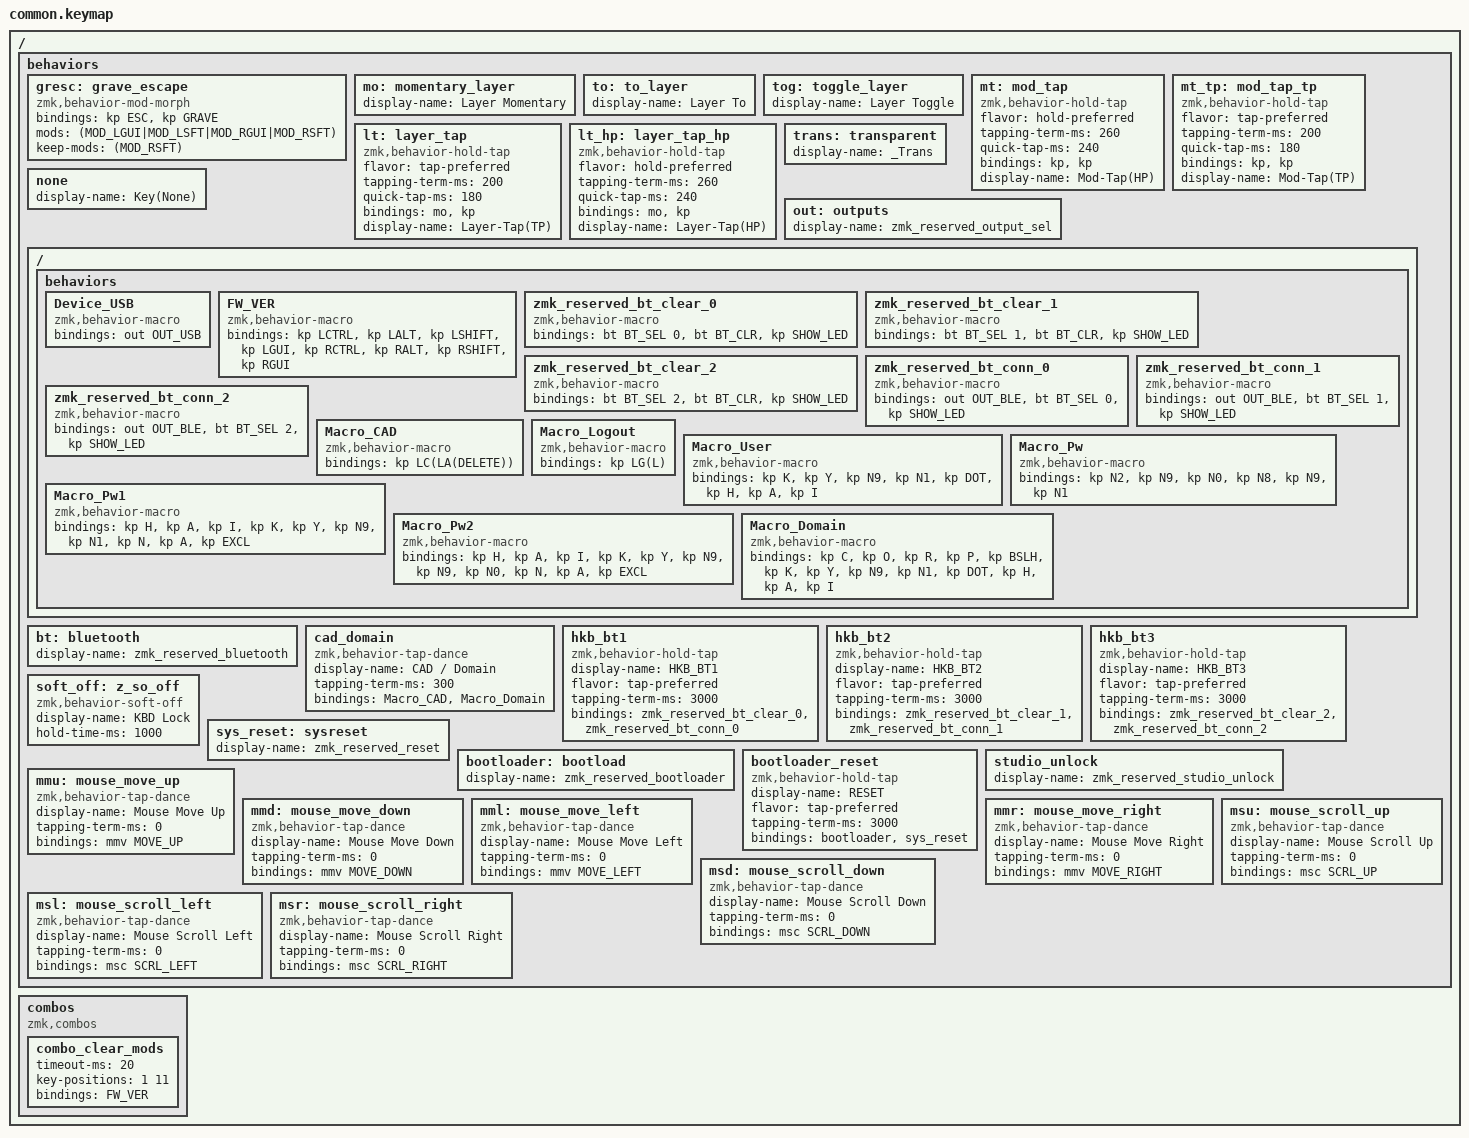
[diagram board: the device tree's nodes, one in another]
/*
 * Copyright (c) 2021 The ZMK Contributors
 *
 * SPDX-License-Identifier: MIT
 */
#define FW_VER zmk_firmware_version_260511
 
#if 1
#define ZMK_BEHAVIORS_OMIT_CAPS_WORD        // &caps_word
#define ZMK_BEHAVIORS_OMIT_KT               // &kt, Key Toggle
#define ZMK_BEHAVIORS_OMIT_KEY_REPEAT       // &key_repeat, Key Repeat
#define ZMK_BEHAVIORS_OMIT_SK               // &sk, Sticky Key
#define ZMK_BEHAVIORS_OMIT_STICKY_LAYER     // &sl, Sticky Layer
#endif

#include <behaviors.dtsi>
#include <dt-bindings/zmk/keys.h>
#include <dt-bindings/zmk/pointing.h>
#include <dt-bindings/zmk/bt.h>
#include <dt-bindings/zmk/outputs.h>

/ {
    behaviors {
        //output ~ with RShift
        gresc: grave_escape {
            compatible = "zmk,behavior-mod-morph";
            #binding-cells = <0>;
            bindings = <&kp ESC>, <&kp GRAVE>;
            mods = <(MOD_LGUI|MOD_LSFT|MOD_RGUI|MOD_RSFT)>;
            keep-mods = <(MOD_RSFT)>;
        };

        mo: momentary_layer { display-name = "Layer Momentary"; };
        to: to_layer { display-name = "Layer To"; };
        tog: toggle_layer { display-name = "Layer Toggle"; };

        // mt default: hold preferred. Rename it.
        mt: mod_tap {
            compatible = "zmk,behavior-hold-tap";
            #binding-cells = <2>;
            flavor = "hold-preferred";
            tapping-term-ms = <260>;
            quick-tap-ms = <240>;
            bindings = <&kp>, <&kp>;
            display-name = "Mod-Tap(HP)";
        };

        // mt_tp tap preferred
        mt_tp: mod_tap_tp {
            compatible = "zmk,behavior-hold-tap";
            #binding-cells = <2>;
            flavor = "tap-preferred";
            tapping-term-ms = <200>;
            quick-tap-ms = <180>;
            bindings = <&kp>, <&kp>;
            display-name = "Mod-Tap(TP)";
        };

        // lt default: tap preferred. Rename it.
        lt: layer_tap {
            compatible = "zmk,behavior-hold-tap";
            #binding-cells = <2>;
            flavor = "tap-preferred";
            tapping-term-ms = <200>;
            quick-tap-ms = <180>;
            bindings = <&mo>, <&kp>;
            display-name = "Layer-Tap(TP)";
        };

        // lt_hp:  hold preferred
        lt_hp: layer_tap_hp {
            compatible = "zmk,behavior-hold-tap";
            #binding-cells = <2>;
            flavor = "hold-preferred";
            tapping-term-ms = <260>;
            quick-tap-ms = <240>;
            bindings = <&mo>, <&kp>;
            display-name = "Layer-Tap(HP)";
        };
        
        trans: transparent { display-name = "_Trans"; };
        none: none { display-name = "Key(None)"; };
        
        #if 1
        out: outputs { display-name = "zmk_reserved_output_sel"; };
        ZMK_MACRO(Device_USB, bindings = <&out OUT_USB>;)

        bt: bluetooth { display-name = "zmk_reserved_bluetooth"; };
        
        #define SHOW_LED 0xAB //A5-AF Reserved
        ZMK_MACRO(FW_VER, bindings = <&kp LCTRL &kp LALT &kp LSHIFT &kp LGUI &kp RCTRL &kp RALT &kp RSHIFT &kp RGUI>;)
        ZMK_MACRO(zmk_reserved_bt_clear_0, bindings = <&bt BT_SEL 0>, <&bt BT_CLR>, <&kp SHOW_LED>;)
        ZMK_MACRO(zmk_reserved_bt_clear_1, bindings = <&bt BT_SEL 1>, <&bt BT_CLR>, <&kp SHOW_LED>;)
        ZMK_MACRO(zmk_reserved_bt_clear_2, bindings = <&bt BT_SEL 2>, <&bt BT_CLR>, <&kp SHOW_LED>;)
        ZMK_MACRO(zmk_reserved_bt_conn_0,  bindings = <&out OUT_BLE>, <&bt BT_SEL 0>, <&kp SHOW_LED>;)
        ZMK_MACRO(zmk_reserved_bt_conn_1,  bindings = <&out OUT_BLE>, <&bt BT_SEL 1>, <&kp SHOW_LED>;)
        ZMK_MACRO(zmk_reserved_bt_conn_2,  bindings = <&out OUT_BLE>, <&bt BT_SEL 2>, <&kp SHOW_LED>;)

        ZMK_MACRO(Macro_CAD,
            bindings = <&kp LC(LA(DELETE))>;
        )
        ZMK_MACRO(Macro_Logout,
            bindings = <&kp LG(L)>;
        )
        ZMK_MACRO(Macro_User,
            bindings = <&kp K &kp Y &kp N9 &kp N1 &kp DOT &kp H &kp A &kp I>;
        )
        ZMK_MACRO(Macro_Pw,
            bindings = <&kp N2 &kp N9 &kp N0 &kp N8 &kp N9 &kp N1>;
        )
        ZMK_MACRO(Macro_Pw1,
            bindings = <&kp H &kp A &kp I &kp K &kp Y &kp N9 &kp N1 &kp N &kp A &kp EXCL>;
        )
        ZMK_MACRO(Macro_Pw2,
            bindings = <&kp H &kp A &kp I &kp K &kp Y &kp N9 &kp N9 &kp N0 &kp N &kp A &kp EXCL>;
        )
        ZMK_MACRO(Macro_Domain,
            bindings = <&kp C &kp O &kp R &kp P &kp BSLH &kp K &kp Y &kp N9 &kp N1 &kp DOT &kp H &kp A &kp I>;
        )

        cad_domain: cad_domain {
            compatible = "zmk,behavior-tap-dance";
            display-name = "CAD / Domain";
            #binding-cells = <0>;
            tapping-term-ms = <300>;
            bindings = <&Macro_CAD>, <&Macro_Domain>;
        };

        hkb_bt1: hkb_bt1 {
            compatible = "zmk,behavior-hold-tap";
            display-name = "HKB_BT1";
            #binding-cells = <2>;
            flavor = "tap-preferred";
            tapping-term-ms = <3000>;  // delay amount in ms
            bindings = <&zmk_reserved_bt_clear_0>, <&zmk_reserved_bt_conn_0>;
        };
        hkb_bt2: hkb_bt2 {
            compatible = "zmk,behavior-hold-tap";
            display-name = "HKB_BT2";
            #binding-cells = <2>;
            flavor = "tap-preferred";
            tapping-term-ms = <3000>;  // delay amount in ms
            bindings = <&zmk_reserved_bt_clear_1>, <&zmk_reserved_bt_conn_1>;
        };
        hkb_bt3: hkb_bt3 {
            compatible = "zmk,behavior-hold-tap";
            display-name = "HKB_BT3";
            #binding-cells = <2>;
            flavor = "tap-preferred";
            tapping-term-ms = <3000>;  // delay amount in ms
            bindings = <&zmk_reserved_bt_clear_2>, <&zmk_reserved_bt_conn_2>;
        };
        //
        soft_off: z_so_off {
            compatible = "zmk,behavior-soft-off";
            display-name = "KBD Lock";
            #binding-cells = <0>;
            hold-time-ms = <1000>;
        };
        sys_reset: sysreset { display-name = "zmk_reserved_reset"; };
        bootloader: bootload { display-name = "zmk_reserved_bootloader"; };
        
        bootloader_reset:bootloader_reset {
            compatible = "zmk,behavior-hold-tap";
            display-name = "RESET";
            #binding-cells = <2>;
            flavor = "tap-preferred";
            tapping-term-ms = <3000>;  // delay amount in ms
            bindings = <&bootloader>, <&sys_reset>;
        };
        
        studio_unlock: studio_unlock { display-name = "zmk_reserved_studio_unlock"; };
        #endif
        
        //mouse move
        mmu:mouse_move_up {
            compatible = "zmk,behavior-tap-dance";
            display-name = "Mouse Move Up";
            #binding-cells = <0>;
            tapping-term-ms = <0>;
            bindings = <&mmv MOVE_UP>;
        };
        mmd:mouse_move_down {
            compatible = "zmk,behavior-tap-dance";
            display-name = "Mouse Move Down";
            #binding-cells = <0>;
            tapping-term-ms = <0>;
            bindings = <&mmv MOVE_DOWN>;
        };
        mml:mouse_move_left {
            compatible = "zmk,behavior-tap-dance";
            display-name = "Mouse Move Left";
            #binding-cells = <0>;
            tapping-term-ms = <0>;
            bindings = <&mmv MOVE_LEFT>;
        };
        mmr:mouse_move_right {
            compatible = "zmk,behavior-tap-dance";
            display-name = "Mouse Move Right";
            #binding-cells = <0>;
            tapping-term-ms = <0>;
            bindings = <&mmv MOVE_RIGHT>;
        };
        //mouse scroll
        msu:mouse_scroll_up {
            compatible = "zmk,behavior-tap-dance";
            display-name = "Mouse Scroll Up";
            #binding-cells = <0>;
            tapping-term-ms = <0>;
            bindings = <&msc SCRL_UP>;
        };
        msd:mouse_scroll_down {
            compatible = "zmk,behavior-tap-dance";
            display-name = "Mouse Scroll Down";
            #binding-cells = <0>;
            tapping-term-ms = <0>;
            bindings = <&msc SCRL_DOWN>;
        };
        msl:mouse_scroll_left {
            compatible = "zmk,behavior-tap-dance";
            display-name = "Mouse Scroll Left";
            #binding-cells = <0>;
            tapping-term-ms = <0>;
            bindings = <&msc SCRL_LEFT>;
        };
        msr:mouse_scroll_right {
            compatible = "zmk,behavior-tap-dance";
            display-name = "Mouse Scroll Right";
            #binding-cells = <0>;
            tapping-term-ms = <0>;
            bindings = <&msc SCRL_RIGHT>;
        };
    };
    combos {
        compatible = "zmk,combos";
        combo_clear_mods {
            timeout-ms = <20>;
            key-positions = <1 11>; // 1!  and -_
            bindings = <&FW_VER>;
        };
    };
};
